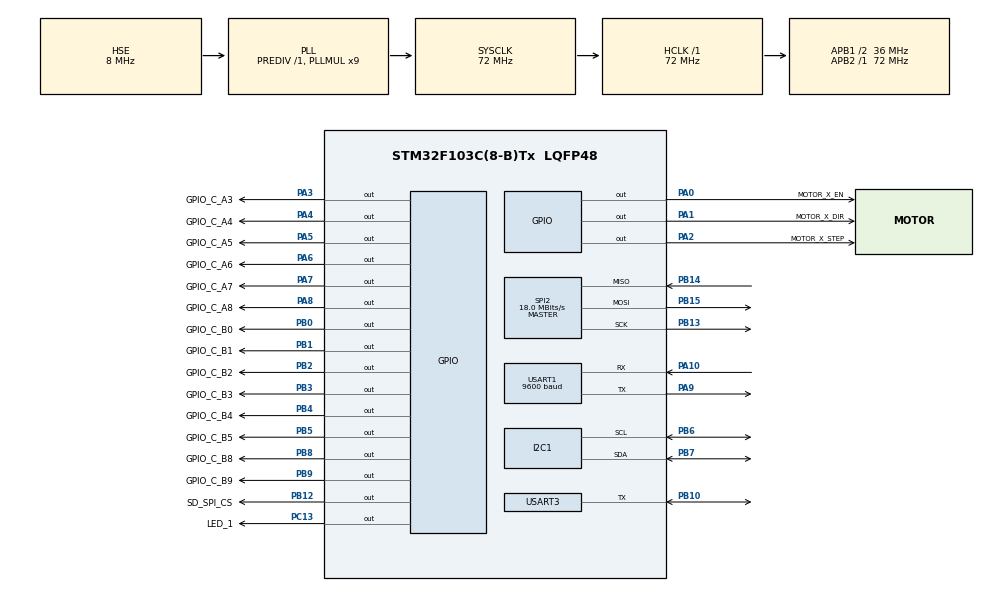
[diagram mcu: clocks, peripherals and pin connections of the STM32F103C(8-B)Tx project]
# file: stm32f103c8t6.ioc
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Dma.Request0=USART1_TX
Dma.Request1=USART1_RX
Dma.USART1_RX.1.Direction=DMA_PERIPH_TO_MEMORY
Dma.USART1_RX.1.Instance=DMA1_Channel5
Dma.USART1_RX.1.MemDataAlignment=DMA_MDATAALIGN_BYTE
Dma.USART1_RX.1.MemInc=DMA_MINC_ENABLE
Dma.USART1_RX.1.Mode=DMA_NORMAL
Dma.USART1_RX.1.PeriphDataAlignment=DMA_PDATAALIGN_BYTE
Dma.USART1_RX.1.PeriphInc=DMA_PINC_DISABLE
Dma.USART1_RX.1.Priority=DMA_PRIORITY_LOW
Dma.USART1_TX.0.Direction=DMA_MEMORY_TO_PERIPH
Dma.USART1_TX.0.Instance=DMA1_Channel4
Dma.USART1_TX.0.MemDataAlignment=DMA_MDATAALIGN_BYTE
Dma.USART1_TX.0.MemInc=DMA_MINC_ENABLE
Dma.USART1_TX.0.Mode=DMA_NORMAL
Dma.USART1_TX.0.PeriphDataAlignment=DMA_PDATAALIGN_BYTE
Dma.USART1_TX.0.PeriphInc=DMA_PINC_DISABLE
Dma.USART1_TX.0.Priority=DMA_PRIORITY_LOW
FATFS._FS_LOCK=1
FATFS._FS_RPATH=2
FATFS._FS_TINY=0
FATFS._MAX_SS=1024
FATFS._MIN_SS=512
FATFS._USE_LFN=1
FATFS._USE_TRIM=0
I2C1.I2C_Mode=I2C_Fast
Mcu.Family=STM32F1
Mcu.Name=STM32F103C(8-B)Tx
Mcu.Package=LQFP48
NVIC.DMA1_Channel4_IRQn=true\:0\:0\:false\:false\:true\:false\:true\:true
NVIC.DMA1_Channel5_IRQn=true\:0\:0\:false\:false\:true\:false\:true\:true
NVIC.PriorityGroup=NVIC_PRIORITYGROUP_4
NVIC.TIM2_IRQn=true\:0\:0\:false\:false\:true\:true\:true\:true
NVIC.USART1_IRQn=true\:0\:0\:false\:false\:true\:true\:true\:true
NVIC.USART3_IRQn=true\:0\:0\:false\:false\:true\:true\:true\:true
PA0-WKUP.GPIO_Label=MOTOR_X_EN
PA0-WKUP.GPIO_Speed=GPIO_SPEED_FREQ_HIGH
PA0-WKUP.Signal=GPIO_Output
PA1.GPIO_Label=MOTOR_X_DIR
PA1.GPIO_Speed=GPIO_SPEED_FREQ_HIGH
PA1.PinState=GPIO_PIN_RESET
PA1.Signal=GPIO_Output
PA10.Mode=Asynchronous
PA10.Signal=USART1_RX
PA13.Mode=Serial_Wire
PA13.Signal=SYS_JTMS-SWDIO
PA14.Mode=Serial_Wire
PA14.Signal=SYS_JTCK-SWCLK
PA2.GPIO_Label=MOTOR_X_STEP
PA2.GPIO_Speed=GPIO_SPEED_FREQ_HIGH
PA2.Signal=GPIO_Output
PA3.GPIO_Label=GPIO_C_A3
PA3.GPIO_Speed=GPIO_SPEED_FREQ_HIGH
PA3.Signal=GPIO_Output
PA4.GPIO_Label=GPIO_C_A4
PA4.GPIO_Speed=GPIO_SPEED_FREQ_HIGH
PA4.Signal=GPIO_Output
PA5.GPIO_Label=GPIO_C_A5
PA5.GPIO_Speed=GPIO_SPEED_FREQ_HIGH
PA5.Signal=GPIO_Output
PA6.GPIO_Label=GPIO_C_A6
PA6.GPIO_Speed=GPIO_SPEED_FREQ_HIGH
PA6.Signal=GPIO_Output
PA7.GPIO_Label=GPIO_C_A7
PA7.GPIO_Speed=GPIO_SPEED_FREQ_HIGH
PA7.Signal=GPIO_Output
PA8.GPIO_Label=GPIO_C_A8
PA8.GPIO_Speed=GPIO_SPEED_FREQ_HIGH
PA8.Signal=GPIO_Output
PA9.Mode=Asynchronous
PA9.Signal=USART1_TX
PB0.GPIO_Label=GPIO_C_B0
PB0.GPIO_Speed=GPIO_SPEED_FREQ_HIGH
PB0.Signal=GPIO_Output
PB1.GPIO_Label=GPIO_C_B1
PB1.GPIO_Speed=GPIO_SPEED_FREQ_HIGH
PB1.Signal=GPIO_Output
PB10.Mode=Half_duplex(single_wire_mode)
PB10.Signal=USART3_TX
PB12.GPIO_Label=SD_SPI_CS
PB12.GPIO_Speed=GPIO_SPEED_FREQ_HIGH
PB12.PinState=GPIO_PIN_RESET
PB12.Signal=GPIO_Output
PB13.GPIO_Speed=GPIO_SPEED_FREQ_HIGH
PB13.Mode=Full_Duplex_Master
PB13.Signal=SPI2_SCK
PB14.Mode=Full_Duplex_Master
PB14.Signal=SPI2_MISO
PB15.GPIO_Speed=GPIO_SPEED_FREQ_HIGH
PB15.Mode=Full_Duplex_Master
PB15.Signal=SPI2_MOSI
PB2.GPIO_Label=GPIO_C_B2
PB2.GPIO_Speed=GPIO_SPEED_FREQ_HIGH
PB2.Signal=GPIO_Output
PB3.GPIO_Label=GPIO_C_B3
PB3.GPIO_Speed=GPIO_SPEED_FREQ_HIGH
PB3.PinState=GPIO_PIN_RESET
PB3.Signal=GPIO_Output
PB4.GPIO_Label=GPIO_C_B4
PB4.GPIO_Speed=GPIO_SPEED_FREQ_HIGH
PB4.Signal=GPIO_Output
PB5.GPIO_Label=GPIO_C_B5
PB5.GPIO_Speed=GPIO_SPEED_FREQ_HIGH
PB5.Signal=GPIO_Output
PB6.Mode=I2C
PB6.Signal=I2C1_SCL
PB7.Mode=I2C
PB7.Signal=I2C1_SDA
PB8.GPIO_Label=GPIO_C_B8
PB8.GPIO_Speed=GPIO_SPEED_FREQ_HIGH
PB8.Signal=GPIO_Output
PB9.GPIO_Label=GPIO_C_B9
PB9.GPIO_Speed=GPIO_SPEED_FREQ_HIGH
PB9.PinState=GPIO_PIN_RESET
PB9.Signal=GPIO_Output
PC13-TAMPER-RTC.GPIO_Label=LED_1
PC13-TAMPER-RTC.GPIO_ModeDefaultOutputPP=GPIO_MODE_OUTPUT_PP
PC13-TAMPER-RTC.GPIO_PuPd=GPIO_NOPULL
PC13-TAMPER-RTC.GPIO_Speed=GPIO_SPEED_FREQ_HIGH
PC13-TAMPER-RTC.PinState=GPIO_PIN_RESET
PC13-TAMPER-RTC.Signal=GPIO_Output
PD0-OSC_IN.Mode=HSE-External-Oscillator
PD0-OSC_IN.Signal=RCC_OSC_IN
PD1-OSC_OUT.Mode=HSE-External-Oscillator
PD1-OSC_OUT.Signal=RCC_OSC_OUT
ProjectManager.HeapSize=0x200
ProjectManager.StackSize=0x400
ProjectManager.TargetToolchain=Makefile
RCC.AHBFreq_Value=72000000
RCC.APB1CLKDivider=RCC_HCLK_DIV2
RCC.APB1Freq_Value=36000000
RCC.APB1TimFreq_Value=72000000
RCC.APB2Freq_Value=72000000
RCC.APB2TimFreq_Value=72000000
RCC.HCLKFreq_Value=72000000
RCC.PLLMUL=RCC_PLL_MUL9
RCC.PLLSourceVirtual=RCC_PLLSOURCE_HSE
RCC.SYSCLKFreq_VALUE=72000000
RCC.SYSCLKSource=RCC_SYSCLKSOURCE_PLLCLK
RCC.USBFreq_Value=72000000
SPI2.BaudRatePrescaler=SPI_BAUDRATEPRESCALER_2
SPI2.CalculateBaudRate=18.0 MBits/s
SPI2.Direction=SPI_DIRECTION_2LINES
SPI2.Mode=SPI_MODE_MASTER
SPI2.VirtualType=VM_MASTER
TIM2.AutoReloadPreload=TIM_AUTORELOAD_PRELOAD_ENABLE
TIM2.Period=49999
TIM2.Prescaler=0
USART1.BaudRate=9600
USART1.VirtualMode=VM_ASYNC
USART3.VirtualMode=VM_ASYNC
VP_FATFS_VS_Generic.Mode=User_defined
VP_TIM2_VS_ClockSourceINT.Mode=Internal
board=custom

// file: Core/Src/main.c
/* USER CODE BEGIN Header */
/**
 ******************************************************************************
 * @file           : main.c
 * @brief          : Main program body
 ******************************************************************************
 * @attention
 *
 * Copyright (c) 2024 STMicroelectronics.
 * All rights reserved.
 *
 * This software is licensed under terms that can be found in the LICENSE file
 * in the root directory of this software component.
 * If no LICENSE file comes with this software, it is provided AS-IS.
 *
 ******************************************************************************
 */
/* USER CODE END Header */
#include "main.h"
#include "fatfs.h"

/* USER CODE BEGIN Includes */
// cimo +
#include "helper.h"
#include "localization.h"
#include "serial_command.h"
// #include "display_i2c_command.h"
// #include "sd_spi_command.h"
// #include "tmc2209_command.h"
/* USER CODE END Includes */

I2C_HandleTypeDef hi2c1;

SPI_HandleTypeDef hspi2;

TIM_HandleTypeDef htim2;

UART_HandleTypeDef huart1;
UART_HandleTypeDef huart3;
DMA_HandleTypeDef hdma_usart1_tx;
DMA_HandleTypeDef hdma_usart1_rx;

void SystemClock_Config(void);
static void MX_GPIO_Init(void);
static void MX_DMA_Init(void);
static void MX_USART1_UART_Init(void);
static void MX_I2C1_Init(void);
static void MX_SPI2_Init(void);
static void MX_USART3_UART_Init(void);
static void MX_TIM2_Init(void);

/* USER CODE BEGIN 0 */
// cimo +
uint32_t previousTimeLed = 0;
uint32_t previousTimeI2cLcd = 0;
uint32_t previousTimeTmc2209 = 0;
/* USER CODE END 0 */

int main(void)
{

    /* MCU Configuration--------------------------------------------------------*/

    /* Reset of all peripherals, Initializes the Flash interface and the Systick. */
    HAL_Init();

    /* Configure the system clock */
    SystemClock_Config();

    /* Initialize all configured peripherals */
    MX_GPIO_Init();
    MX_DMA_Init();
    MX_USART1_UART_Init();
    MX_FATFS_Init();
    MX_I2C1_Init();
    MX_SPI2_Init();
    MX_USART3_UART_Init();
    MX_TIM2_Init();
    /* USER CODE BEGIN 2 */
    // cimo +
    localizationInit("en");

    serialCommandAsynchronousInit(&huart1);
    serialCommandSingleWireInit(&huart3);

    // lcdI2cCommandInit(&hi2c1);

    // sdSpiCommandInit(&hspi2);

    // tmc2209CommandInit(&huart3, &htim2);
    /* USER CODE END 2 */

    /* Infinite loop */
    /* USER CODE BEGIN WHILE */
    while (1)
    {
        if (helperMillisecondElapsed(&previousTimeLed, 100))
        {
            // HAL_GPIO_TogglePin(LED_1_GPIO_Port, LED_1_Pin);
        }

        if (helperMillisecondElapsed(&previousTimeI2cLcd, 1000))
        {
            // lcdI2cCommandLoop("loop3");
        }

        if (helperMillisecondElapsed(&previousTimeTmc2209, 5000))
        {
            // tmc2209CommandLoop();

            serialSingleWireSendMessage("Sended");
        }
        /* USER CODE END WHILE */

    }
}

void SystemClock_Config(void)
{
    RCC_OscInitTypeDef RCC_OscInitStruct = {0};
    RCC_ClkInitTypeDef RCC_ClkInitStruct = {0};

    /** Initializes the RCC Oscillators according to the specified parameters
     * in the RCC_OscInitTypeDef structure.
     */
    RCC_OscInitStruct.OscillatorType = RCC_OSCILLATORTYPE_HSE;
    RCC_OscInitStruct.HSEState = RCC_HSE_ON;
    RCC_OscInitStruct.HSEPredivValue = RCC_HSE_PREDIV_DIV1;
    RCC_OscInitStruct.HSIState = RCC_HSI_ON;
    RCC_OscInitStruct.PLL.PLLState = RCC_PLL_ON;
    RCC_OscInitStruct.PLL.PLLSource = RCC_PLLSOURCE_HSE;
    RCC_OscInitStruct.PLL.PLLMUL = RCC_PLL_MUL9;
    if (HAL_RCC_OscConfig(&RCC_OscInitStruct) != HAL_OK)
    {
        Error_Handler();
    }

    /** Initializes the CPU, AHB and APB buses clocks
     */
    RCC_ClkInitStruct.ClockType = RCC_CLOCKTYPE_HCLK | RCC_CLOCKTYPE_SYSCLK | RCC_CLOCKTYPE_PCLK1 | RCC_CLOCKTYPE_PCLK2;
    RCC_ClkInitStruct.SYSCLKSource = RCC_SYSCLKSOURCE_PLLCLK;
    RCC_ClkInitStruct.AHBCLKDivider = RCC_SYSCLK_DIV1;
    RCC_ClkInitStruct.APB1CLKDivider = RCC_HCLK_DIV2;
    RCC_ClkInitStruct.APB2CLKDivider = RCC_HCLK_DIV1;

    if (HAL_RCC_ClockConfig(&RCC_ClkInitStruct, FLASH_LATENCY_2) != HAL_OK)
    {
        Error_Handler();
    }
}

static void MX_I2C1_Init(void)
{

    hi2c1.Instance = I2C1;
    hi2c1.Init.ClockSpeed = 400000;
    hi2c1.Init.DutyCycle = I2C_DUTYCYCLE_2;
    hi2c1.Init.OwnAddress1 = 0;
    hi2c1.Init.AddressingMode = I2C_ADDRESSINGMODE_7BIT;
    hi2c1.Init.DualAddressMode = I2C_DUALADDRESS_DISABLE;
    hi2c1.Init.OwnAddress2 = 0;
    hi2c1.Init.GeneralCallMode = I2C_GENERALCALL_DISABLE;
    hi2c1.Init.NoStretchMode = I2C_NOSTRETCH_DISABLE;
    if (HAL_I2C_Init(&hi2c1) != HAL_OK)
    {
        Error_Handler();
    }
}

static void MX_SPI2_Init(void)
{

    /* SPI2 parameter configuration*/
    hspi2.Instance = SPI2;
    hspi2.Init.Mode = SPI_MODE_MASTER;
    hspi2.Init.Direction = SPI_DIRECTION_2LINES;
    hspi2.Init.DataSize = SPI_DATASIZE_8BIT;
    hspi2.Init.CLKPolarity = SPI_POLARITY_LOW;
    hspi2.Init.CLKPhase = SPI_PHASE_1EDGE;
    hspi2.Init.NSS = SPI_NSS_SOFT;
    hspi2.Init.BaudRatePrescaler = SPI_BAUDRATEPRESCALER_2;
    hspi2.Init.FirstBit = SPI_FIRSTBIT_MSB;
    hspi2.Init.TIMode = SPI_TIMODE_DISABLE;
    hspi2.Init.CRCCalculation = SPI_CRCCALCULATION_DISABLE;
    hspi2.Init.CRCPolynomial = 10;
    if (HAL_SPI_Init(&hspi2) != HAL_OK)
    {
        Error_Handler();
    }
}

static void MX_TIM2_Init(void)
{

    TIM_ClockConfigTypeDef sClockSourceConfig = {0};
    TIM_MasterConfigTypeDef sMasterConfig = {0};

    htim2.Instance = TIM2;
    htim2.Init.Prescaler = 0;
    htim2.Init.CounterMode = TIM_COUNTERMODE_UP;
    htim2.Init.Period = 49999;
    htim2.Init.ClockDivision = TIM_CLOCKDIVISION_DIV1;
    htim2.Init.AutoReloadPreload = TIM_AUTORELOAD_PRELOAD_ENABLE;
    if (HAL_TIM_Base_Init(&htim2) != HAL_OK)
    {
        Error_Handler();
    }
    sClockSourceConfig.ClockSource = TIM_CLOCKSOURCE_INTERNAL;
    if (HAL_TIM_ConfigClockSource(&htim2, &sClockSourceConfig) != HAL_OK)
    {
        Error_Handler();
    }
    sMasterConfig.MasterOutputTrigger = TIM_TRGO_RESET;
    sMasterConfig.MasterSlaveMode = TIM_MASTERSLAVEMODE_DISABLE;
    if (HAL_TIMEx_MasterConfigSynchronization(&htim2, &sMasterConfig) != HAL_OK)
    {
        Error_Handler();
    }
}

static void MX_USART1_UART_Init(void)
{

    huart1.Instance = USART1;
    huart1.Init.BaudRate = 9600;
    huart1.Init.WordLength = UART_WORDLENGTH_8B;
    huart1.Init.StopBits = UART_STOPBITS_1;
    huart1.Init.Parity = UART_PARITY_NONE;
    huart1.Init.Mode = UART_MODE_TX_RX;
    huart1.Init.HwFlowCtl = UART_HWCONTROL_NONE;
    huart1.Init.OverSampling = UART_OVERSAMPLING_16;
    if (HAL_UART_Init(&huart1) != HAL_OK)
    {
        Error_Handler();
    }
}

static void MX_USART3_UART_Init(void)
{

    huart3.Instance = USART3;
    huart3.Init.BaudRate = 115200;
    huart3.Init.WordLength = UART_WORDLENGTH_8B;
    huart3.Init.StopBits = UART_STOPBITS_1;
    huart3.Init.Parity = UART_PARITY_NONE;
    huart3.Init.Mode = UART_MODE_TX_RX;
    huart3.Init.HwFlowCtl = UART_HWCONTROL_NONE;
    huart3.Init.OverSampling = UART_OVERSAMPLING_16;
    if (HAL_HalfDuplex_Init(&huart3) != HAL_OK)
    {
        Error_Handler();
    }
}

static void MX_DMA_Init(void)
{

    /* DMA controller clock enable */
    __HAL_RCC_DMA1_CLK_ENABLE();

    /* DMA interrupt init */
    /* DMA1_Channel4_IRQn interrupt configuration */
    HAL_NVIC_SetPriority(DMA1_Channel4_IRQn, 0, 0);
    HAL_NVIC_EnableIRQ(DMA1_Channel4_IRQn);
    /* DMA1_Channel5_IRQn interrupt configuration */
    HAL_NVIC_SetPriority(DMA1_Channel5_IRQn, 0, 0);
    HAL_NVIC_EnableIRQ(DMA1_Channel5_IRQn);
}

static void MX_GPIO_Init(void)
{
    GPIO_InitTypeDef GPIO_InitStruct = {0};

    /* GPIO Ports Clock Enable */
    __HAL_RCC_GPIOC_CLK_ENABLE();
    __HAL_RCC_GPIOD_CLK_ENABLE();
    __HAL_RCC_GPIOA_CLK_ENABLE();
    __HAL_RCC_GPIOB_CLK_ENABLE();

    /*Configure GPIO pin Output Level */
    HAL_GPIO_WritePin(LED_1_GPIO_Port, LED_1_Pin, GPIO_PIN_RESET);

    /*Configure GPIO pin Output Level */
    HAL_GPIO_WritePin(GPIOA, MOTOR_X_EN_Pin | MOTOR_X_DIR_Pin | MOTOR_X_STEP_Pin | GPIO_C_A3_Pin | GPIO_C_A4_Pin | GPIO_C_A5_Pin | GPIO_C_A6_Pin | GPIO_C_A7_Pin | GPIO_C_A8_Pin, GPIO_PIN_RESET);

    /*Configure GPIO pin Output Level */
    HAL_GPIO_WritePin(GPIOB, GPIO_C_B0_Pin | GPIO_C_B1_Pin | GPIO_C_B2_Pin | SD_SPI_CS_Pin | GPIO_C_B3_Pin | GPIO_C_B4_Pin | GPIO_C_B5_Pin | GPIO_C_B8_Pin | GPIO_C_B9_Pin, GPIO_PIN_RESET);

    /*Configure GPIO pin : LED_1_Pin */
    GPIO_InitStruct.Pin = LED_1_Pin;
    GPIO_InitStruct.Mode = GPIO_MODE_OUTPUT_PP;
    GPIO_InitStruct.Pull = GPIO_NOPULL;
    GPIO_InitStruct.Speed = GPIO_SPEED_FREQ_HIGH;
    HAL_GPIO_Init(LED_1_GPIO_Port, &GPIO_InitStruct);

    /*Configure GPIO pins : MOTOR_X_EN_Pin MOTOR_X_DIR_Pin MOTOR_X_STEP_Pin GPIO_C_A3_Pin
                             GPIO_C_A4_Pin GPIO_C_A5_Pin GPIO_C_A6_Pin GPIO_C_A7_Pin
                             GPIO_C_A8_Pin */
    GPIO_InitStruct.Pin = MOTOR_X_EN_Pin | MOTOR_X_DIR_Pin | MOTOR_X_STEP_Pin | GPIO_C_A3_Pin | GPIO_C_A4_Pin | GPIO_C_A5_Pin | GPIO_C_A6_Pin | GPIO_C_A7_Pin | GPIO_C_A8_Pin;
    GPIO_InitStruct.Mode = GPIO_MODE_OUTPUT_PP;
    GPIO_InitStruct.Pull = GPIO_NOPULL;
    GPIO_InitStruct.Speed = GPIO_SPEED_FREQ_HIGH;
    HAL_GPIO_Init(GPIOA, &GPIO_InitStruct);

    /*Configure GPIO pins : GPIO_C_B0_Pin GPIO_C_B1_Pin GPIO_C_B2_Pin SD_SPI_CS_Pin
                             GPIO_C_B3_Pin GPIO_C_B4_Pin GPIO_C_B5_Pin GPIO_C_B8_Pin
                             GPIO_C_B9_Pin */
    GPIO_InitStruct.Pin = GPIO_C_B0_Pin | GPIO_C_B1_Pin | GPIO_C_B2_Pin | SD_SPI_CS_Pin | GPIO_C_B3_Pin | GPIO_C_B4_Pin | GPIO_C_B5_Pin | GPIO_C_B8_Pin | GPIO_C_B9_Pin;
    GPIO_InitStruct.Mode = GPIO_MODE_OUTPUT_PP;
    GPIO_InitStruct.Pull = GPIO_NOPULL;
    GPIO_InitStruct.Speed = GPIO_SPEED_FREQ_HIGH;
    HAL_GPIO_Init(GPIOB, &GPIO_InitStruct);

}

void Error_Handler(void)
{
    __disable_irq();
    while (1)
    {
    }
}
